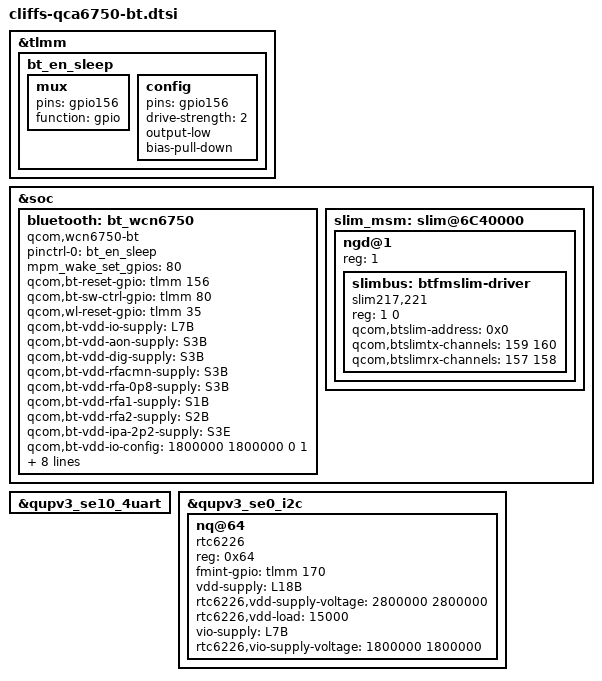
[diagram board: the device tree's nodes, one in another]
#include <dt-bindings/interconnect/qcom,cliffs.h>

&tlmm {
	bt_en_sleep: bt_en_sleep {
		mux {
			pins = "gpio156";
			function = "gpio";
		};

		config {
			pins = "gpio156";
			drive-strength = <2>;
			output-low;
			bias-pull-down;
		};
	};
};

&soc {
	bluetooth: bt_wcn6750 {
		compatible = "qcom,wcn6750-bt";
		pinctrl-names = "default";
		pinctrl-0 = <&bt_en_sleep>;
                /* List of GPIOs to be setup for interrupt wakeup capable*/
		mpm_wake_set_gpios = <80>;
		qcom,bt-reset-gpio = <&tlmm 156 0>; /* BT_EN */
		qcom,bt-sw-ctrl-gpio = <&tlmm 80 0>; /* SW_CTRL */
		qcom,wl-reset-gpio = <&tlmm 35 0>; /* WL_EN */

		qcom,bt-vdd-io-supply = <&L7B>;  /* IO */
		qcom,bt-vdd-aon-supply = <&S3B>;
		qcom,bt-vdd-dig-supply = <&S3B>; /* BT_CX_MX */
		qcom,bt-vdd-rfacmn-supply = <&S3B>;
		qcom,bt-vdd-rfa-0p8-supply = <&S3B>;
		qcom,bt-vdd-rfa1-supply = <&S1B>; /*RFA 1p7*/
		qcom,bt-vdd-rfa2-supply = <&S2B>; /*RFA 1p2*/
		qcom,bt-vdd-ipa-2p2-supply = <&S3E>; /*IPA 2p2*/

		/* max voltage are set to regulator max voltage supported */
		qcom,bt-vdd-io-config = <1800000 1800000 0 1>;
		qcom,bt-vdd-aon-config = <968000 1040000 0 1>;
		qcom,bt-vdd-dig-config = <968000 1040000 0 1>;
		qcom,bt-vdd-rfacmn-config  = <968000 1040000 0 1>;
		qcom,bt-vdd-rfa-0p8-config  = <968000 1040000 0 1>;
		qcom,bt-vdd-rfa1-config = <1856000 2040000 0 1>;
		qcom,bt-vdd-rfa2-config = <1256000 1408000 0 1>;
		qcom,bt-vdd-ipa-2p2-config = <1600000 2400000 0 1>;
	};

	slim_msm: slim@6C40000 {
		status =  "ok";
		ngd@1 {
			reg = <1>;
			#address-cells = <1>;
			#size-cells = <1>;
			//slimbus child nodes
			slimbus: btfmslim-driver {
				compatible = "slim217,221";
				reg = <1 0>;
				qcom,btslim-address  = <0x0>; /* BT SLIM EP address*/
				qcom,btslimtx-channels = <159 160>; /* slimbus FM_Tx, SCO_Tx channels */
				qcom,btslimrx-channels = <157 158>; /* slimbus SCO_A2DP_Rx A2DP_Rx */
			};
		};
	};
};

//uart instance
&qupv3_se10_4uart{
	status = "ok";
};


// FM changes
&qupv3_se0_i2c {
	status = "ok";
	nq@64 {
		compatible = "rtc6226";
		reg = <0x64>;
		fmint-gpio = <&tlmm 170 0>;
		vdd-supply = <&L18B>;
		rtc6226,vdd-supply-voltage = <2800000 2800000>;
		rtc6226,vdd-load = <15000>;
		vio-supply = <&L7B>;
		rtc6226,vio-supply-voltage = <1800000 1800000>;
	};
};
